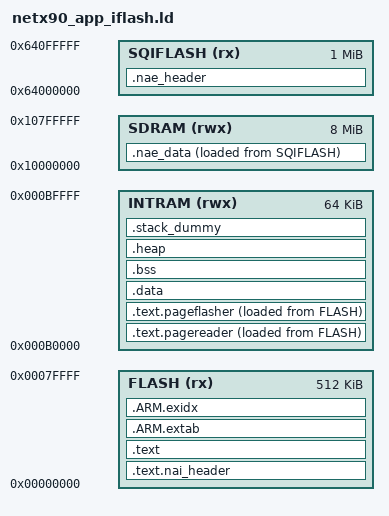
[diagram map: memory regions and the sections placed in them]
/***************************************************************************
 *   Copyright (C) 2017, Hilscher Gesellschaft fuer Systemautomation mbH   *
 *                                                                         *
 *   This program is free software; you can redistribute it and/or modify  *
 *   it under the terms of the GNU General Public License as published by  *
 *   the Free Software Foundation; either version 2 of the License, or     *
 *   (at your option) any later version.                                   *
 *                                                                         *
 *   This program is distributed in the hope that it will be useful,       *
 *   but WITHOUT ANY WARRANTY; without even the implied warranty of        *
 *   MERCHANTABILITY or FITNESS FOR A PARTICULAR PURPOSE.  See the         *
 *   GNU General Public License for more details.                          *
 *                                                                         *
 *   You should have received a copy of the GNU General Public License     *
 *   along with this program; if not, write to the                         *
 *   Free Software Foundation, Inc.,                                       *
 *   59 Temple Place - Suite 330, Boston, MA  02111-1307, USA.             *
 ***************************************************************************/
 
/* Linker script to configure memory regions. */
MEMORY
{
  FLASH     (rx)  : ORIGIN = 0x00000000, LENGTH = 512K
  INTRAM    (rwx) : ORIGIN = 0x000B0000, LENGTH = 64K
  SDRAM     (rwx) : ORIGIN = 0x10000000, LENGTH = 8M
  SQIFLASH  (rx)  : ORIGIN = 0x64000000, LENGTH = 1024K
}

/* Library configurations */
GROUP(libgcc.a libc.a libm.a libnosys.a)

/* Linker script to place sections and symbol values. Should be used together
 * with other linker script that defines memory regions FLASH and RAM.
 * It references following symbols, which must be defined in code:
 *   Reset_Handler : Entry of reset handler
 *
 * It defines following symbols, which code can use without definition:
 *   __exidx_start
 *   __exidx_end
 *   __copy_table_start__
 *   __copy_table_end__
 *   __zero_table_start__
 *   __zero_table_end__
 *   __etext
 *   __data_start__
 *   __preinit_array_start
 *   __preinit_array_end
 *   __init_array_start
 *   __init_array_end
 *   __fini_array_start
 *   __fini_array_end
 *   __data_end__
 *   __bss_start__
 *   __bss_end__
 *   __end__
 *   end
 *   __HeapBase
 *   __HeapLimit
 *   __StackLimit
 *   __StackTop
 *   __stack
 *   __Vectors_End
 *   __Vectors_Size
 */
ENTRY(Reset_Handler)

SECTIONS
{
    .text.nai_header  ORIGIN(FLASH) :
    {
        KEEP(*(.vectors))
        __Vectors_End = .;
        __Vectors_Size = __Vectors_End - __Vectors;
        __end__ = .;
        
        KEEP(*(.app_cpu_hboot_boot_header_nai))
        KEEP(*(.app_cpu_header_nai))
    } > FLASH
    
    .text.pagereader :
    {
        *(.text.PageReader);
        *(.rodata.PageReader);
    } > INTRAM AT > FLASH
    
    .text.pageflasher :
    {
        *(.text.PageFlasher);
        *(.rodata.PageFlasher);
    } > INTRAM AT > FLASH
    
    .text :
    {
        *(.text*)

        KEEP(*(.init))
        KEEP(*(.fini))

        /* .ctors */
        *crtbegin.o(.ctors)
        *crtbegin?.o(.ctors)
        *(EXCLUDE_FILE(*crtend?.o *crtend.o) .ctors)
        *(SORT(.ctors.*))
        *(.ctors)

        /* .dtors */
        *crtbegin.o(.dtors)
        *crtbegin?.o(.dtors)
        *(EXCLUDE_FILE(*crtend?.o *crtend.o) .dtors)
        *(SORT(.dtors.*))
        *(.dtors)

        . = ALIGN(4);
        PROVIDE(tPageReaderFunction = .);
        LONG(ADDR(.text.pagereader));
        LONG(LOADADDR(.text.pagereader));
        LONG(SIZEOF(.text.pagereader));
        KEEP(*(.rodata.pPageReader));
        . = ALIGN(4);
        PROVIDE(tPageFlasherFunction = .);
        LONG(ADDR(.text.pageflasher));
        LONG(LOADADDR(.text.pageflasher));
        LONG(SIZEOF(.text.pageflasher));
        KEEP(*(.rodata.pPageFlasher));
        
        *(.rodata*)

        KEEP(*(.eh_frame*))
        . = ALIGN(4);
    } > FLASH

    .ARM.extab :
    {
        *(.ARM.extab* .gnu.linkonce.armextab.*)
    } > FLASH

    __exidx_start = .;
    .ARM.exidx :
    {
        *(.ARM.exidx* .gnu.linkonce.armexidx.*)
    } > FLASH
    __exidx_end = .;

    /* To copy multiple ROM to RAM sections,
     * uncomment .copy.table section and,
     * define __STARTUP_COPY_MULTIPLE in startup_ARMCMx.S */
    /*
    .copy.table :
    {
        . = ALIGN(4);
        __copy_table_start__ = .;
        LONG (__etext)
        LONG (__data_start__)
        LONG (__data_end__ - __data_start__)
        LONG (__etext2)
        LONG (__data2_start__)
        LONG (__data2_end__ - __data2_start__)
        __copy_table_end__ = .;
    } > FLASH
    */

    /* To clear multiple BSS sections,
     * uncomment .zero.table section and,
     * define __STARTUP_CLEAR_BSS_MULTIPLE in startup_ARMCMx.S */
    /*
    .zero.table :
    {
        . = ALIGN(4);
        __zero_table_start__ = .;
        LONG (__bss_start__)
        LONG (__bss_end__ - __bss_start__)
        LONG (__bss2_start__)
        LONG (__bss2_end__ - __bss2_start__)
        __zero_table_end__ = .;
    } > FLASH
    */

    __etext = .;

    .data : AT (__etext)
    {
        __data_start__ = .;
        *(vtable)
        *(.data*)

        . = ALIGN(4);
        /* preinit data */
        PROVIDE_HIDDEN (__preinit_array_start = .);
        KEEP(*(.preinit_array))
        PROVIDE_HIDDEN (__preinit_array_end = .);

        . = ALIGN(4);
        /* init data */
        PROVIDE_HIDDEN (__init_array_start = .);
        KEEP(*(SORT(.init_array.*)))
        KEEP(*(.init_array))
        PROVIDE_HIDDEN (__init_array_end = .);


        . = ALIGN(4);
        /* finit data */
        PROVIDE_HIDDEN (__fini_array_start = .);
        KEEP(*(SORT(.fini_array.*)))
        KEEP(*(.fini_array))
        PROVIDE_HIDDEN (__fini_array_end = .);

        KEEP(*(.jcr*))
        . = ALIGN(4);
        /* All data end */
        __data_end__ = .;
        
        KEEP(*(.app_cpu_secure_boot_header))

    } > INTRAM

    .bss :
    {
        . = ALIGN(4);
        __bss_start__ = .;
        *(.bss*)
        *(COMMON)
        . = ALIGN(4);
        __bss_end__ = .;
    } > INTRAM

    .heap (COPY):
    {
        __HeapBase = .;
        __end__ = .;
        end = __end__;
        __heap_start__ = .;
        KEEP(*(.heap*))
        __heap_end__ = .;
        __HeapLimit = .;
    } > INTRAM
    

    /* .stack_dummy section doesn't contains any symbols. It is only
     * used for linker to calculate size of stack sections, and assign
     * values to stack symbols later */
    .stack_dummy (COPY):
    {
        __stack_start__ = .;
        KEEP(*(.stack*))
        __stack_end__ = .;
    } > INTRAM

    /* Set stack top to end of RAM, and stack limit move down by
     * size of stack_dummy section */
    __StackTop = ORIGIN(INTRAM) + LENGTH(INTRAM);
    __StackLimit = __StackTop - SIZEOF(.stack_dummy);
    PROVIDE(__stack = __StackTop);

    /* Check if data + heap + stack exceeds RAM limit */
    ASSERT(__StackLimit >= __HeapLimit, "region RAM overflowed with stack")
    
    /* Section prepared for the external SQI Flash content, not evaluated yet. */
    .nae_header (NOLOAD) : 
    {
        __qspi_flash_start__ = .;
        KEEP(*(.app_cpu_hboot_boot_header_nae))
        KEEP(*(.app_cpu_header_nae))
    } > SQIFLASH
    
    .nae_data (NOLOAD) : 
    {
        KEEP(*(.QFlash*))
        . = ALIGN(4);
        KEEP(*(.app_cpu_secure_boot_header))
        __qspi_flash_end__ = .;
    } > SDRAM AT > SQIFLASH
}
